# TC37XPD register map
Vendor: Infineon; Series: ATVMC; File version: 100
CPU: other r0p0, little endian, MPU, FPU, vendor SysTick, 4 interrupt priority bits
Registers are 32-bit, read-write, reset 0x0 unless marked. A register's access mark holds for its fields unless they carry their own. Offsets are from the block's base; [hi:lo] are bit positions; lines under a group give offsets from that group; {n}, {i} and the like mark numbered series.

## SCU (part 1 of 3) — System Control Unit
Base 0xF0036000
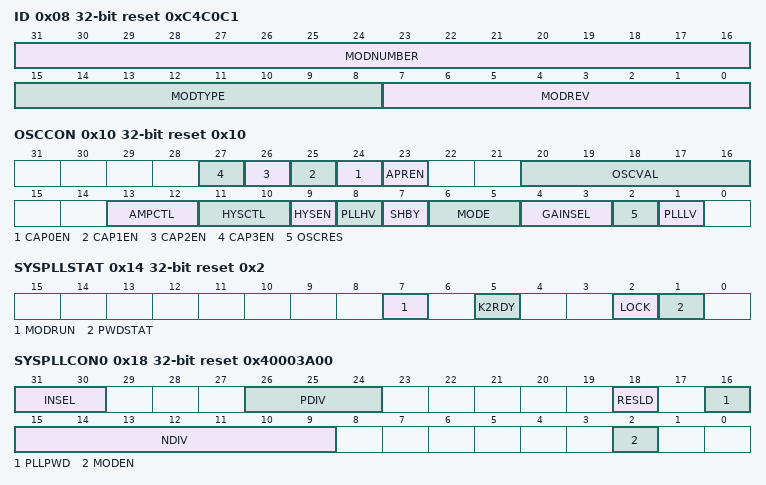
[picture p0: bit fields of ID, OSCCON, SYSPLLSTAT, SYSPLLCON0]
0x08 ID ro reset 0xC4C0C1 — Identification Register resetvalue={System Reset:0x0C4C0C1}
  [31:16] MODNUMBER — Module Number MODNUMBER. This bit field defines the module identification number. The identification number for the SCU is 00C4 H
  [15:8] MODTYPE — Module Type MODTYPE. This bit field is C0 H . It defines a 32 bit module
  [7:0] MODREV — Module Revision Number MODREV. This bit field indicates the revision number of the SCU module C1 H . Bits 5 0 defines the SCU module IP revision number. Bits 7 6 defines the family. This allows a continuous numbering of the revision AND a deviation of the different SCU generations. The revision number starts with 000001 and is incremented when a SCU change is detectable by customer software. MODREV for other variants will be defined by Design Team
0x10 OSCCON access per field reset 0x10 (reset mask 0xFFFFF0B0) — OSC Control Register resetvalue={System Reset:0x10,System Reset:0x258}
  [n+24] CAP{n}EN rw (n=0..3) — Capacitance {n} Enable CAP{n}EN. Total capacitance for each XTAL1 and XTAL2 is the sum of the enabled capacitance 0 to 3.
  [23] APREN rw — Amplitude Regulation Enable APREN. This bit field enables and disables Amplitude Regulation mode. When enabled the bit field GAINSEL limits the maximum gain.
  [20:16] OSCVAL rw — OSC Frequency Value OSCVAL. This bit field defines the divider value that generates the reference clock that is supervised by the oscillator watchdog. f OSC 160 160 OSCCON.OSCVAL 160 160 1 160 160 16 160 MHz.
  [13:12] AMPCTL rw — Amplitude Control
  [11:10] HYSCTL rw — Hysteresis Control
  [9] HYSEN rw — Hysteresis Enable
  [8] PLLHV ro — Oscillator for PLL Valid High Status Bit PLLHV. This bit indicates if the frequency output f osc of the oscillator is below the upper threshold frequency f HV i.e. usable for the DCO part of the PLL. This is checked by the Oscillator Watchdog of the PLL using the backup clock f BACK . By using the crystal s nominal frequency f oscnom the upper threshold calculates as follows f HV f oscnom 1 04 0 29
  [7] SHBY rw — Shaper Bypass SHBY
  [6:5] MODE rw — Oscillator Mode MODE. This bit field defines which mode can be used and if the oscillator entered the Power Saving Mode or not. In Test Mode the shaper can be bypassed even if the oscillator is in the Oscillator Power Saving Mode. This is controlled by the TCU.
  [4:3] GAINSEL rw — Oscillator Gain Selection GAINSEL. In Normal Mode this value should not be changed from the reset value 11 B . When using Vext 3.3V the LVDS bias distributor has to be adjusted to 3.3V supply via P21 LPCR2.PS 0 otherwise the oscillator gain can be too low for a reliable oscillator startup at cold temperature. In case of using Vext 5V the LVDS bias distributor setting stays at the reset value P21 LPCR2.PS 1.
  [2] OSCRES wo — Oscillator Watchdog Reset OSCRES. Always read as zero.
  [1] PLLLV ro — Oscillator for PLL Valid Low Status Bit PLLLV. This bit indicates if the frequency output f osc of the oscillator is above the lower threshold frequency f LV i.e. usable for the DCO part of the PLL. This is checked by the Oscillator Watchdog of the PLL using the backup clock f BACK . By using the crystal s nominal frequency f oscnom the lower threshold calculates as follows f LV f oscnom 0 96 0 31
0x14 SYSPLLSTAT ro reset 0x2 — System PLL Status Register resetvalue={System Reset:0x2,System Reset:0x2}
  [7] MODRUN — Modulation Run MODRUN. This bit indicates if the frequency modulation of the System PLL is activated or not.
  [5] K2RDY — K2 Divider Ready Status K2RDY. This bit indicates whether the K2 divider operates on the configured value. This is of interest when the SYSPLLCON1.K2DIV value is changed. The PLL must be enabled and clocked to set the K2RDY field.
  [2] LOCK — System PLL Lock Status LOCK. In case of a loss of lock the f DCO is kept on the previous constant frequency.
  [1] PWDSTAT — System PLL Power saving Mode Status PWDSTAT
0x18 SYSPLLCON0 access per field reset 0x40003A00 — System PLL Configuration 0 Register resetvalue={System Reset:0x40003A00}
  [31:30] INSEL rw — Input Selection INSEL. This bit field defines as clock source for the two PLLs System PLL and Peripheral PLL .
  [26:24] PDIV rw — P Divider Value PDIV. The value the P Divider operates with is PDIV 1.
  [18] RESLD wo — Restart DCO Lock Detection RESLD. Setting this bit will clear bit SYSPLLSTAT.LOCK and restart the DCO lock detection. Reading this bit returns always a zero.
  [16] PLLPWD rw — System PLL Power Saving Mode PLLPWD. If the PLL has been powered down and is getting re enabled via PLLPWD 1 a wait period of 1 ms has to be applied until it is stable without jitter.
  [15:9] NDIV rw — N Divider Value NDIV. The value the N Divider operates with is NDIV 1.
  [2] MODEN rw — Modulation Enable MODEN. This bit controls the activation of the frequency modulation of the System PLL.
0x1C SYSPLLCON1 reset 0x5 — System PLL Configuration 1 Register resetvalue={System Reset:0x5}
  [2:0] K2DIV — K2 Divider Value K2DIV. The value the K2 Divider operates with is K2DIV 1. While SYSPLLSTAT.K2RDY 0 K2DIV is locked.
0x20 SYSPLLCON2 reset 0x6000 — System PLL Configuration 2 Register resetvalue={System Reset:0x6000}
  [15:0] MODCFG — Modulation Configuration MODCFG. This bit field defines the modulation. MODCFG 9 0 defines the modulation amplitude. Bits MODCFG 9 5 are treated as integer part and bits MODCFG 4 0 as fractional part. Bits MODCFG 15 10 have to be configured with the following setting 0x111101 B .
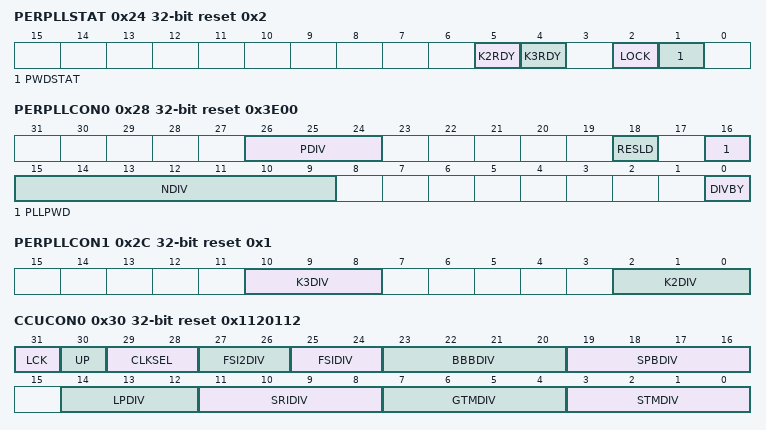
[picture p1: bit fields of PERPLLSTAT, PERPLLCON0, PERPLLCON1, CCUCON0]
0x24 PERPLLSTAT ro reset 0x2 — Peripheral PLL Status Register resetvalue={System Reset:0x2}
  [5] K2RDY — K2 Divider Ready Status K2RDY. This bit indicates whether the K2 divider operates on the configured value. This is of interest when the PERPLLCON1.K2DIV value is changed. The PLL must be enabled and clocked to set the K2RDY field.
  [4] K3RDY — K3 Divider Ready Status K3RDY. This bit indicates whether the K3 divider operates on the configured value. This is of interest when the PERPLLCON1.K3DIV value is changed. The PLL must be enabled and clocked to set the K3RDY field.
  [2] LOCK — Peripheral PLL Lock Status LOCK. In case of a loss of lock the f DCO is kept on the previous constant frequency.
  [1] PWDSTAT — Peripheral PLL Power saving Mode Status PWDSTAT
0x28 PERPLLCON0 access per field reset 0x3E00 — Peripheral PLL Configuration 0 Register resetvalue={System Reset:0x3E00}
  [26:24] PDIV rw — P Divider Value PDIV. The value the P Divider operates with is PDIV 1.
  [18] RESLD wo — Restart DCO Lock Detection RESLD. Setting this bit will clear bit SYSPLLSTAT.LOCK and restart the DCO lock detection. Reading this bit returns always a zero.
  [16] PLLPWD rw — Peripheral PLL Power Saving Mode PLLPWD. If the PLL has been powered down and is getting re enabled via PLLPWD 1 a wait period of 1 ms has to be applied until it is stable without jitter.
  [15:9] NDIV rw — N Divider Value NDIV. The value the N Divider operates with is NDIV 1.
  [0] DIVBY rw — Divider Bypass DIVBY
0x2C PERPLLCON1 reset 0x1 — Peripheral PLL Configuration 1 Register resetvalue={System Reset:0x1}
  [10:8] K3DIV — K3 Divider Value K3DIV. The value the K3 Divider operates with is K3DIV 1. While PERPLLSTAT.K3RDY 0 K3DIV is locked.
  [2:0] K2DIV — K2 Divider Value K2DIV. The value the K2 Divider operates with is K2DIV 1. While PERPLLSTAT.K2RDY 0 K2DIV is locked.
0x30 CCUCON0 access per field reset 0x1120112 (reset mask 0xF9FEFFFE) — CCU Clock Control Register 0 resetvalue={After SSW execution:0x5120112,System Reset:0x3130113}
  [31] LCK ro — Lock Status LCK. This bit indicates if the register can be updated with a new value or if the register is locked and a write action from the bus side has no effect. The lock bit is set when an update of CCUCON0 5 has been requested and released when the update is complete.
  [30] UP wo — Update Request UP. Setting this bit will request an update for CCUCON0 and CCUCON5. Only one UP bit must be set for either CCUCON0 or CCUCON5. This bit always reads as zero.
  [29:28] CLKSEL rw — Clock Selection for Source CLKSEL. This bit field defines the clock source that is used for the clock generation of f sourcex .
  [27:26] FSI2DIV rw — FSI2 Divider Reload Value FSI2DIV
  [25:24] FSIDIV rw — FSI Divider Reload Value FSIDIV
  [23:20] BBBDIV rw — BBB Divider Reload Value BBBDIV. The resulting BBB frequency is configured to f BBB 160 160 f source0 160 160 BBBDIV for all allowed configurations. For BBBDIV 160 160 0000 B the clock is shut off. f source0 could be configured either to f PLL0 CLKSEL 160 160 01 B or f BACK CLKSEL 160 160 00 B
  [19:16] SPBDIV rw — SPB Divider Reload Value SPBDIV. f source0 could be configured either to f PLL CLKSEL 01 B or f BACK CLKSEL 00 B
  [14:12] LPDIV rw — Low Power Divider Reload Value LPDIV. The selected divider is valid for all clocks derived from f XXX with XXX SPB SRI BBB FSI GETH GTM ADAS.
  [11:8] SRIDIV rw — SRI Divider Reload Value SRIDIV. The resulting SRI frequency is configured to f SRI f source0 SRIDIV for the allowed configurations. f source0 could be configured either to f PLL0 CLKSEL 01 B or f BACK CLKSEL 00 B
  [7:4] GTMDIV rw — GTM Divider Reload Value GTMDIV. The resulting GTM frequency is configured to f GTM f SOURCEGTM GTMDIV for the allowed configurations. For GTMDIV 0000 B the clock is shut off.
  [3:0] STMDIV rw — STM Divider Reload Value STMDIV. The resulting STM frequency is configured to f STM xa0 xa0 f source0 xa0 xa0 STMDIV for the allowed configurations. For STMDIV xa0 xa0 0000 B the clock is shut off. f source0 can be configured either to f PLL0 CLKSEL xa0 xa0 01 B or f BACK CLKSEL xa0 xa0 00 B
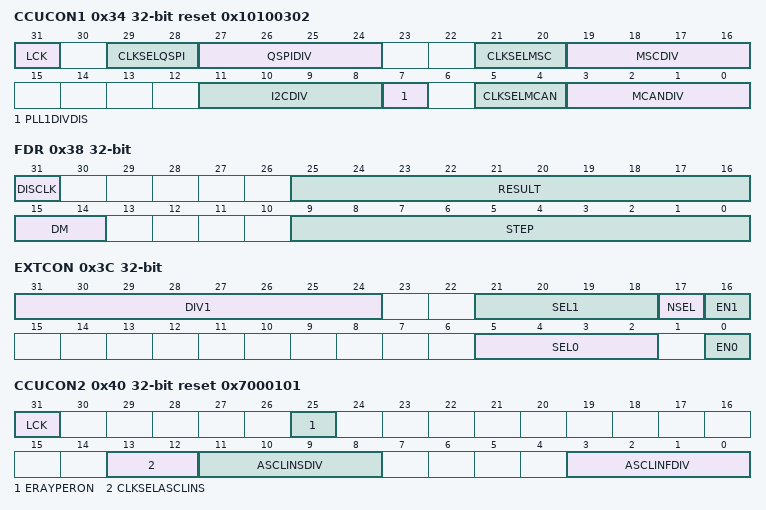
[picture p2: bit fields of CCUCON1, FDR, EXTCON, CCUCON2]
0x34 CCUCON1 access per field reset 0x10100302 — CCU Clock Control Register 1 resetvalue={System Reset:0x10100302}
  [31] LCK ro — Lock Status LCK. This bit indicates if the register can be updated with a new value or if the register is locked and a write action from the bus side has no effect. The lock bit is set when at least one bit field is changed and released when this change is executed.
  [29:28] CLKSELQSPI rw — Clock Selection for QSPI CLKSELQSPI. This bit field defines the clock source that is used for the clock generation of f SOURCEQSPI . For switching between two non zero configurations the following sequence has to be applied First step is to switch to 00 B . Second step is to switch to the new target configuration.
  [27:24] QSPIDIV rw — QSPI Divider Reload Value QSPIDIV. The resulting QSPI frequency is configured to f QSPI 160 160 f SOURCEQSPI 160 160 QSPIDIV for the allowed configurations. For QSPIDIV 160 160 0000 B the clock is shut off.
  [21:20] CLKSELMSC rw — Clock Selection for MSC CLKSELMSC. This bit field defines the clock source that is used for the clock generation of f SOURCEMSC . For switching between two non zero configurations the following sequence has to be applied First step is to switch to 00 B . Second step is to switch to the new target configuration.
  [19:16] MSCDIV rw — MSC Divider Reload Value MSCDIV. The resulting MSC frequency is configured to f MSC 160 160 f SOURCEMSC 160 160 MSCDIV for the allowed configurations. For MSCDIV 160 160 0000 B the clock is shut off.
  [11:8] I2CDIV rw — I2C Divider Reload Value I2CDIV. The resulting I2C frequency is configured to f I2C xa0 xa0 f SOURCE2 xa0 xa0 I2CDIV for the allowed configurations. For I2CDIV xa0 xa0 0000 B the clock is shut off.
  [7] PLL1DIVDIS rw — Divider Disable for fPLL1 PLL1DIVDIS. Depending on CCUCON0.CLKSEL this bit selects whether f source1 is half f pll1 .
  [5:4] CLKSELMCAN rw — Clock Selection for MCAN CLKSELMCAN. This bit field defines the clock source that is used for the clock generation of f SOURCEMCAN . For switching between two non zero configurations the following sequence has to be applied First step is to switch to 00 B . Second step is to switch to the new target configuration.
  [3:0] MCANDIV rw — MCAN Divider Reload Value MCANDIV. The resulting MCAN frequency is configured to f MCANI 160 160 f source1 160 160 MCANDIV for the allowed configurations. For MCANDIV 160 160 0000 B the clock is shut off.
0x38 FDR access per field — Fractional Divider Register resetvalue={System Reset:0x0}
  [31] DISCLK rw — Disable Clock DISCLK
  [25:16] RESULT ro — Result Value RESULT. In Normal Divider Mode RESULT acts as reload counter addition 1 . In Fractional Divider Mode this bit field contains the result of the addition RESULT STEP. If DM is written with 01 B or 10 B RESULT is loaded with 3FF H .
  [15:14] DM rw — Divider Mode DM. These bit fields determine the functionality of the fractional divider block.
  [9:0] STEP rw — Step Value STEP. In Normal Divider Mode STEP contains the reload value for RESULT. In Fractional Divider Mode this bit field determines the 10 bit value that is added to RESULT with each input clock cycle.
0x3C EXTCON — External Clock Control Register resetvalue={System Reset:0x0}
  [31:24] DIV1 — External Clock Divider for EXTCLK1 DIV1. This value defines the reload value of the divider that generates f OUT out of f SPB f OUT f SPB DIV1 1 . The divider itself is cleared each time bit EN1 is cleared.
  [21:18] SEL1 — External Clock Select for EXTCLK1 SEL1. This bit field defines the clock source that is selected as the output for pin EXTCLK1. This bit field can be overruled in Test Mode via the TCU.
  [17] NSEL — Negation Selection NSEL. This bit can be overruled in Test Mode via the TCU.
  [16] EN1 — External Clock Enable for EXTCLK1 EN1. If the generation of the external clock signal is disabled the signal is tied to zero. This bit can be overruled in Test Mode via the TCU.
  [5:2] SEL0 — External Clock Select for EXTCLK0 SEL0. This bit field defines the clock source that is selected as output for pin EXTCLK0. This bit field can be overruled in Test Mode via the TCU.
  [0] EN0 — External Clock Enable for EXTCLK0 EN0. If the generation of the external clock signal is disabled the signal is tied to zero. This bit field can be overruled in Test Mode via the TCU.
0x40 CCUCON2 access per field reset 0x7000101 — CCU Clock Control Register 2 resetvalue={System Reset:0x7000101}
  [31] LCK ro — Lock Status LCK. This bit indicates if the register can be updated with a new value or if the register is locked and a write action from the bus side has no effect. The lock bit is set when at least one bit field is changed and released when this change is executed.
  [25] ERAYPERON rw — Power Safe SwitchOff for ERAY Clock ERAYPERON. This bit is used to control the ERAY peripheral clock f ERAY for power saving purposes if the logic is not used by the application.
  [13:12] CLKSELASCLINS rw — Clock Selection for ASCLINS CLKSELASCLINS. This bit field defines the clock source that is used for the clock generation of f ASCLINS . For switching between two non zero configurations the following sequence has to be applied First step is to switch to 00 B . Second step is to switch to the new target configuration.
  [11:8] ASCLINSDIV rw — ASCLIN Slow Divider Reload Value ASCLINSDIV. The resulting ASCLIN frequency is configured to f ASCLINSI f source1 ASCLINSDIV for the allowed configurations. For ASCLINSDIV 0000 B the clock is shut off. f source1 could be configured either to f PLL1 CLKSEL 01 B or f BACK CLKSEL 00 B
  [3:0] ASCLINFDIV rw — ASCLIN Fast Divider Reload Value ASCLINFDIV. The resulting ASCLIN frequency is configured to f ASCLINF f source2 ASCLINFDIV for the allowed configurations. For ASCLINFDIV 0000 B the clock is shut off. f source2 could be configured either to f PLL2 CLKSEL 01 B or f BACK CLKSEL 00 B
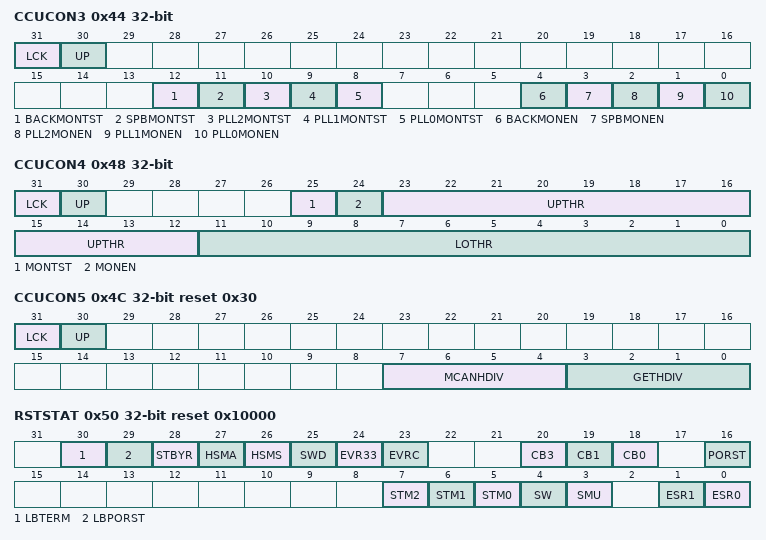
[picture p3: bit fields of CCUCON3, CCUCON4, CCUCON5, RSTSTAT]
0x44 CCUCON3 access per field — CCU Clock Control Register 3 resetvalue={System Reset:0x0}
  [31] LCK ro — Lock Status LCK. This bit indicates if the register can be updated with a new value or if the register is locked and a write action from the bus side has no effect. The lock bit is set when an update of CCUCON3 4 has been requested and released when the update is complete.
  [30] UP wo — Update Request UP. Setting this bit will request an update for CCUCON3 and CCUCON4. Only one UP bit must be set for either CCUCON3 or CCUCON4. This bit always reads as zero.
  [12] BACKMONTST rw — Backup Clock Monitor Test BACKMONTST. The test enable bit is not a direct trigger for the alarm but an inhibit for the clock to be monitored. This is to test the monitoring logic itself as well.
  [11] SPBMONTST rw — SPB Clock Monitor Test SPBMONTST. The test enable bit is not a direct trigger for the alarm but an inhibit for the clock to be monitored. This is to test the monitoring logic itself as well.
  [10] PLL2MONTST rw — PLL2 Clock Monitor Test PLL2MONTST. The test enable bit is not a direct trigger for the alarm but an inhibit for the clock to be monitored. This is to test the monitoring logic itself as well.
  [9] PLL1MONTST rw — PLL1 Clock Monitor Test PLL1MONTST. The test enable bit is not a direct trigger for the alarm but an inhibit for the clock to be monitored. This is to test the monitoring logic itself as well.
  [8] PLL0MONTST rw — PLL0 Clock Monitor Test PLL0MONTST. The test enable bit is not a direct trigger for the alarm but an inhibit for the clock to be monitored. This is to test the monitoring logic itself as well.
  [4] BACKMONEN rw — Backup Clock Monitor Enable BACKMONEN
  [3] SPBMONEN rw — SPB Clock Monitor Enable SPBMONEN
  [2] PLL2MONEN rw — PLL2 Clock Monitor Enable PLL2MONEN
  [1] PLL1MONEN rw — PLL1 Clock Monitor Enable PLL1MONEN
  [0] PLL0MONEN rw — PLL0 Clock Monitor Enable PLL0MONEN
0x48 CCUCON4 access per field — CCU Clock Control Register 4 resetvalue={System Reset:0x0}
  [31] LCK ro — Lock Status LCK. This bit indicates if the register can be updated with a new value or if the register is locked and a write action from the bus side has no effect. The lock bit is set when an update of CCUCON3 4 has been requested and released when the update is complete.
  [30] UP wo — Update Request UP. Setting this bit will request an update for CCUCON3 and CCUCON4. Only one UP bit must be set for either CCUCON3 or CCUCON4. This bit always reads as zero.
  [25] MONTST rw — Backup Clock Monitor Test MONTST. Set this bit to 1 to test alarm generation. The test enable bit is a direct trigger for the alarm.
  [24] MONEN rw — Backup Clock Monitor Enable MONEN
  [23:12] UPTHR rw — Backup Clock Monitor Upper Threshold UPTHR. upper threshold 512 f PLL0 1.1 100 MHz For proper operation and to avoid false alarms the monitor needs to be disabled via MONEN 0 before changing setting the threshold values.
  [11:0] LOTHR rw — Backup Clock Monitor Lower Threshold LOTHR. lower threshold 512 f PLL0 0.9 100 MHz For proper operation and to avoid false alarms the monitor needs to be disabled via MONEN 0 before changing setting the threshold values.
0x4C CCUCON5 access per field reset 0x30 — CCU Clock Control Register 5 resetvalue={System Reset:0x30}
  [31] LCK ro — Lock Status LCK. This bit indicates if the register can be updated with a new value or if the register is locked and a write action from the bus side has no effect. The lock bit is set when an update of CCUCON0 5 has been requested and released when the update is complete.
  [30] UP wo — Update Request UP. Setting this bit will request an update for CCUCON0 and CCUCON5. Only one UP bit must be set either CCUCON0 or CCUCON5. This bit always reads as zero.
  [7:4] MCANHDIV rw — MCANH Divider Reload Value MCANHDIV. The resulting MCANH frequency is configured to f MCANH f SOURCE0 MCANHDIV for the allowed configurations. For MCANHDIV 0000 B the clock is shut off.
  [3:0] GETHDIV rw — GETH Divider Reload Value GETHDIV. The resulting GETH frequency is configured to f GETH xa0 xa0 f source0 xa0 xa0 GETHDIV for the allowed configurations. For GETHDIV xa0 xa0 0000 B the clock is shut off. f source0 could be configured either to f PLL0 CLKSEL xa0 xa0 01 B or f BACK CLKSEL xa0 xa0 00 B GETHDIV must be enabled 0 during an application reset to allow firmware related installation tasks.
0x50 RSTSTAT ro reset 0x10000 (reset mask 0xE00FFFFF) — Reset Status Register resetvalue={Cold PowerOn Reset:0x3810000,Cold PowerOn Reset:0x13810000,Cold PowerOn Reset:0x10010000}
  [30] LBTERM — LBIST was properly terminated. This bitfield indicates if the LBIST was terminated properly. This bitfield is cleared when the RSTCON2.CLRC is set.
  [29] LBPORST — LBIST termination due to PORST. This bitfield indicates if the LBIST was early terminated due to the occurrence of a Power On Reset. If the status of this bitfield is 0 the application must still check the LBTERM to check if the LBIST was terminated properly. This bitfield is cleared when the RSTCON2.CLRC is set.
  [28] STBYR — Reset Request Trigger Reset Status for Standby Regulator Watchdog STBYR STBYR
  [27] HSMA — Reset Request Trigger Reset Status for HSM Application Reset HSM A HSMA
  [26] HSMS — Reset Request Trigger Reset Status for HSM System Reset HSM S HSMS
  [25] SWD — Reset Request Trigger Reset Status for Supply Watchdog SWD SWD. The Supply Watchdog trigger is described in Power Management Controller 8220 Supply Monitoring 8221 chapter
  [24] EVR33 — Reset Request Trigger Reset Status for EVR33 EVR33
  [23] EVRC — Reset Request Trigger Reset Status for EVRC EVRC
  [20] CB3 — Reset Request Trigger Reset Status for Cerberus Application Reset CB3
  [19] CB1 — Reset Request Trigger Reset Status for Cerberus Debug Reset CB1
  [18] CB0 — Reset Request Trigger Reset Status for Cerberus System Reset CB0
  [16] PORST — Reset Request Trigger Reset Status for PORST PORST. This bit is also set if the bits CB0 CB1 and CB3 are set in parallel.
  [7] STM2 — Reset Request Trigger Reset Status for STM2 Compare Match If Product has STM2 STM2
  [6] STM1 — Reset Request Trigger Reset Status for STM1 Compare Match If Product has STM1 STM1
  [5] STM0 — Reset Request Trigger Reset Status for STM0 Compare Match STM0
  [4] SW — Reset Request Trigger Reset Status for SW SW
  [3] SMU — Reset Request Trigger Reset Status for SMU SMU. See SMU section for SMU trigger sources including Watchdog Timers
  [1] ESR1 — Reset Request Trigger Reset Status for ESR1 ESR1
  [0] ESR0 — Reset Request Trigger Reset Status for ESR0 ESR0
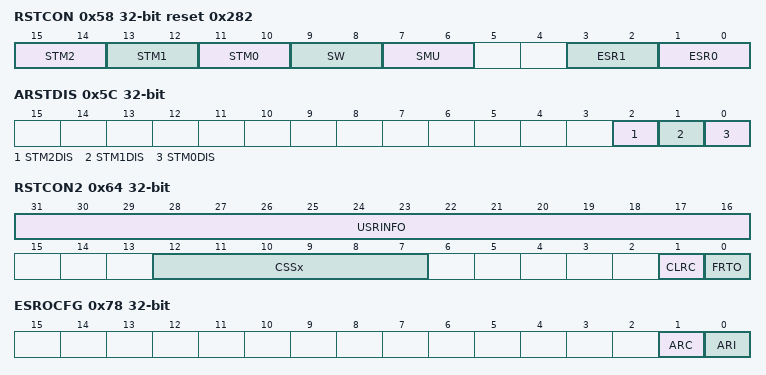
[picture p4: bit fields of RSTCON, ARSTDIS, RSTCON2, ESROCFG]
0x58 RSTCON reset 0x282 — Reset Configuration Register resetvalue={PowerOn Reset:0x282,PowerOn Reset:0x282}
  [15:14] STM2 — STM2 Reset Request Trigger Reset Configuration If Product has STM2 STM2. This bit field defines which reset is generated by a reset request trigger from STM2 compare match reset.
  [13:12] STM1 — STM1 Reset Request Trigger Reset Configuration If Product has STM1 STM1. This bit field defines which reset is generated by a reset request trigger from STM1 compare match reset.
  [11:10] STM0 — STM0 Reset Request Trigger Reset Configuration STM0. This bit field defines which reset is generated by a reset request trigger from STM0 compare match reset.
  [9:8] SW — SW Reset Request Trigger Reset Configuration SW. This bit field defines which reset is generated by a reset request trigger from software reset.
  [7:6] SMU — SMU Reset Request Trigger Reset Configuration SMU. This bit field defines which reset is generated by a reset request trigger from SMU reset.
  [3:2] ESR1 — ESR1 Reset Request Trigger Reset Configuration ESR1. This bit field defines which reset is generated by a reset request trigger from ESR1 reset.
  [1:0] ESR0 — ESR0 Reset Request Trigger Reset Configuration ESR0. This bit field defines which reset is generated by a reset request trigger from ESR0 reset.
0x5C ARSTDIS — Application Reset Disable Register resetvalue={PowerOn Reset:0x0}
  [2] STM2DIS — STM2 Disable Reset STM2DIS. This bit field defines if an Application Reset leads to an reset for the STM2.
  [1] STM1DIS — STM1 Disable Reset STM1DIS. This bit field defines if an Application Reset leads to an reset for the STM1.
  [0] STM0DIS — STM0 Disable Reset STM0DIS. This bit field defines if an Application Reset leads to an reset for the STM0.
0x60 SWRSTCON wo — Software Reset Configuration Register resetvalue={PowerOn Reset:0x0,PowerOn Reset:0x0}
  [1] SWRSTREQ — Software Reset Request SWRSTREQ. This bit is automatically cleared and read always as zero.
0x64 RSTCON2 access per field — Additional Reset Control Register resetvalue={Cold PowerOn Reset:0x0,Cold PowerOn Reset:0x0}
  [31:16] USRINFO rw — User Information USRINFO. User data register Cleared only on Cold Power on reset . This may be used by an application to store information which must survive all warm resets
  [12:7] CSSx ro — CPU x Shutdown State Reached CSSx. The state of CPU x before the last warm reset. If any bit is zero after an Application Reset or higher then it is possible that SRAM content could have been corrupted by the reset. For products with fewer CPUs only the LSBs are active and unused upper bits will always read x2018 1 x2019 . For products with no MCDS miniMCDS MCDSlight the bit will always read 1 .
  [1] CLRC wo — Clear Cold Reset Status CLRC. This bit simultaneously clears the sticky status bits which may indicate any previous cold reset i.e. RSTSTAT.STBYR RSTSTAT.SWD RSTSTAT.EVR33 RSTSTAT.EVRC RSTSTAT.PORST RSTSTAT.LBPORST and RSTSTAT.LBTERM .
  [0] FRTO rw — Force Reset Timeout FRTO
{0x70+4i} ESRCFGx[{i}] (i=0..1) group
  0x00 ESRCFGx reset 0x100 — ESR0 Input Configuration Register resetvalue={System Reset:0x100}
    [8:7] EDCON — Edge Detection Control EDCON. This bit field defines the edges that lead to an ESRx trigger of the synchronous path.
0x78 ESROCFG access per field (reset mask 0xFFFFFFF0) — ESR Output Configuration Register resetvalue={System Reset:0x0}
  [1] ARC wo — Application Reset Indicator Clear ARC. Read as 0
  [0] ARI ro — Application Reset Indicator ARI. This bit is set when an Application Reset request trigger occurs and cleared by writing to ARC. When the ARI bit is set and an ESR pin is configured as a reset output the corresponding ESR input will not re trigger a reset. This prevents feedback of the reset indication causing a new reset request. Extension of the reset by an external ESR source is handled by SSW. Observed reset value after boot will depend upon ARI mode.
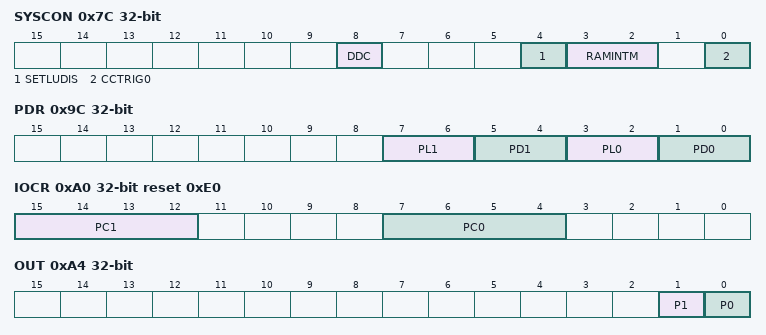
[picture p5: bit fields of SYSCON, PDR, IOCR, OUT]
0x7C SYSCON access per field — System Control Register resetvalue={System Reset:0x0}
  [8] DDC rw — Disable DXCPL DDC. Drives signal to TCU
  [4] SETLUDIS wo — Set Latch Update Disable SETLUDIS. Setting this bit sets bit STSTAT.LUDIS. Clearing this bit has no effect. This bit reads always as zero.
  [3:2] RAMINTM wo — RAM Integrity Modify RAMINTM
  [0] CCTRIG0 rw — Capture Compare Trigger 0 CCTRIG0. This bit is used to trigger the Synchronous Start feature of the CCU6.
0x80 CCUCON6 — CCU Clock Control Register 6 resetvalue={System Reset:0x0}
  [5:0] CPU0DIV — CPU0 Divider Reload Value CPU0DIV. The resulting CPU0 frequency performance is configured to f CPU0 xa0 xa0 f SRI xa0 xa0 64 xa0 xa0 CPU0DIV xa0 xa0 64. For CPU0DIV xa0 xa0 000000 B f CPU0 xa0 xa0 f SRI .
0x84 CCUCON7 — CCU Clock Control Register 7 resetvalue={System Reset:0x0}
  [5:0] CPU1DIV — CPU1 Divider Reload Value CPU1DIV. The resulting CPU1 frequency performance is configured to f CPU1 xa0 xa0 f SRI xa0 xa0 64 xa0 xa0 CPU1DIV xa0 xa0 64. For CPU1DIV xa0 xa0 000000 B f CPU1 xa0 xa0 f SRI .
0x88 CCUCON8 — CCU Clock Control Register 8 resetvalue={System Reset:0x0}
  [5:0] CPU2DIV — CPU2 Divider Reload Value CPU2DIV. The resulting CPU2 frequency performance is configured to f CPU2 xa0 xa0 f SRI xa0 xa0 64 xa0 xa0 CPU2DIV xa0 xa0 64. For CPU2DIV xa0 xa0 000000 B f CPU2 xa0 xa0 f SRI .
0x9C PDR — ESR Pad Driver Mode Register resetvalue={System Reset:0x0}
  [7:6] PL1 — Pad Level Selection for ESR Pins 1 PL1. See PDR register description in PORTs chapter
  [5:4] PD1 — Pad Driver Mode for ESR Pins 1 PD1. See PDR register description in PORTs chapter
  [3:2] PL0 — Pad Level Selection for ESR Pins 0 PL0. See PDR register description in PORTs chapter
  [1:0] PD0 — Pad Driver Mode for ESR Pins 0 PD0. See PDR register description in PORTs chapter
0xA0 IOCR reset 0xE0 (reset mask 0xFFFF0FFF) — Input Output Control Register resetvalue={System Reset:0x0E0}
  [15:12] PC1 — Control for ESR1 Pin PC1. This bit field defines the ESR1 functionality according to the coding tables. The reset value of SCU IOCR.PC1 is influenced by HWCFG6 and PMSWCR5.TRISTREQ. When a cold reset is activated and HWCFG6 1 then PC1 is reset to 2H and ESR1 will have input pull up mode. If HWCFG6 0 then PC1 is reset to 0H and ESR1 will have tri state mode. PC1 and the ESR1 reset state can also be configured by software with the PMSWCR5.TRISTREQ bit. PMSWCR5.TRISTREQ is not affected by warm reset or wake up from standby so the IOCR.PC1 reset value is configured as per the state of the TRISTREQ bit prior to the warm reset
  [7:4] PC0 — Control for ESR0 Pin PC0. This bit field defines the ESR0 functionality according to the coding tables.
0xA4 OUT — ESR Output Register resetvalue={System Reset:0x0}
  [1] P1 — Output Bit 1 P1. This bit determines the level at the output pin ESR x if the output is selected as GPIO output. Px can also be set cleared by control bits of the OMR register.
  [0] P0 — Output Bit 1 P1. This bit determines the level at the output pin ESR x if the output is selected as GPIO output. Px can also be set cleared by control bits of the OMR register.
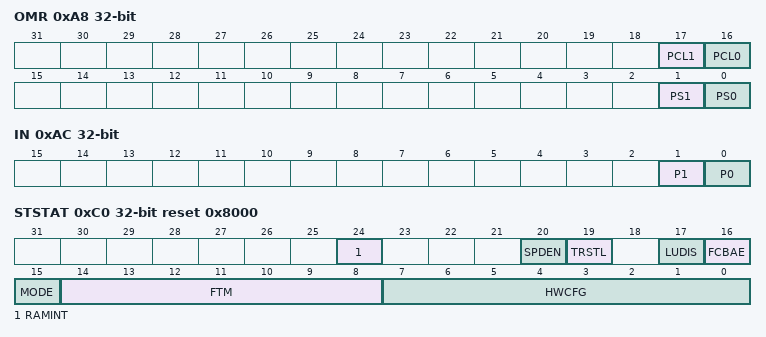
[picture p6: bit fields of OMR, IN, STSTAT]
0xA8 OMR wo — ESR Output Modification Register resetvalue={System Reset:0x0}
  [17] PCL1 — ESRx Pin Clear Bit 1 PCL1. Setting this bit will clear or toggle the corresponding bit in the port output register OUT. Reading this bit returns 0.
  [16] PCL0 — ESRx Pin Clear Bit 1 PCL1. Setting this bit will clear or toggle the corresponding bit in the port output register OUT. Reading this bit returns 0.
  [1] PS1 — ESRx Pin Set Bit 1 PS1. Setting this bit will set or toggle the corresponding bit in the output register OUT. Reading this bit returns 0.
  [0] PS0 — ESRx Pin Set Bit 1 PS1. Setting this bit will set or toggle the corresponding bit in the output register OUT. Reading this bit returns 0.
0xAC IN ro (reset mask 0xFFFFFFF0) — ESR Input Register resetvalue={System Reset:0x0}
  [1] P1 — Input Bit 1 P1. This bit indicates the level at the input pin ESR x.
  [0] P0 — Input Bit 1 P1. This bit indicates the level at the input pin ESR x.
0xC0 STSTAT ro reset 0x8000 (reset mask 0xFFF0FF00) — Start up Status Register resetvalue={PowerOn Reset:0x08000}
  [24] RAMINT — RAM Content Security Integrity RAMINT. In normal operation this bit can be set or cleared by the application via SYSCON.RAMINTM . If a test boot mode is entered the bit is automatically cleared and cannot be set again in test mode because the content may have been altered This bit is reset only by a cold power on reset.
  [20] SPDEN — Single Pin DAP Mode Enable SPDEN
  [19] TRSTL — TRSTL Status TRSTL. This bit simply displays the value of TRST .
  [17] LUDIS — Latch Update Disable LUDIS. This bit can be set by setting bit SYSCON.SETLUDIS. Reset value of this bit is 0
  [16] FCBAE — Flash Config. Sector Access Enable FCBAE. This bit can be cleared by setting bit STCON.CFCBAE. This bit can be set by setting bit STCON.SFCBAE. Reset value of this bit is 0
  [15] MODE — MODE MODE. This bit indicates if the Test Mode is entered or not.
  [14:8] FTM — Firmware Test Setting FTM. This bit field contains the value that is used by the boot software in Test Mode. This Bit field is updated in Test Mode by the TCU. In Normal Mode this bit field is updated with 0000000 B and should be ignored by the boot software.
  [7:0] HWCFG — Hardware Configuration Setting HWCFG. This bit field contains the value that is used by the boot software. This bit field is updated in case of an Application Reset with the content by register SWRSTCON.SWCFG if bit SWRSTCON.SWBOOT AND RSTSTAT.SW are set. This bit field is updated in case of an Application Reset with the content of the latches of pins P14.2 P14.5 P10.5 P10.6 if bit SWRSTCON.SWBOOT OR RSTSTAT.SW are cleared and bit STSTAT.LUDIS is cleared. This bit field is left unchanged in case of an Application Reset and is not updated with the content of the latches of pins P14.2 P14.5 P10.5 P10.6 if bit SWRSTCON.SWBOOT OR RSTSTAT.SW are cleared and bit STSTAT.LUDIS is set. The observed reset value after boot depends upon the state of the HWCFG pins
